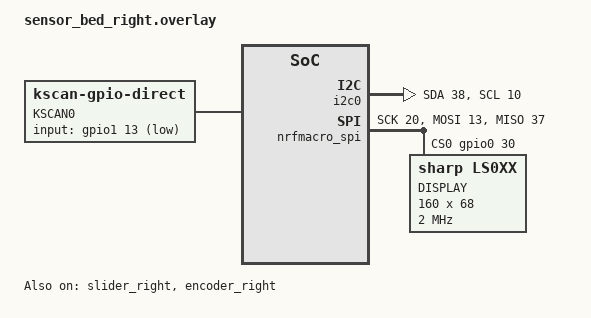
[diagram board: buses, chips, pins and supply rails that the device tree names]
/*
 * Copyright (c) 2020 The ZMK Contributors
 *
 * SPDX-License-Identifier: MIT
 */

#include "sensor_bed.dtsi"

/*  adjust matrix transform for pepripheral split */
&default_transform {
	col-offset = <1>;
};

/* Define kscan pins */
/ {
	kscan0: kscan0 {
		compatible = "zmk,kscan-gpio-direct";
		label = "KSCAN0";

		input-gpios
	  = <&gpio1 13 (GPIO_ACTIVE_LOW | GPIO_PULL_UP)>
    ;
	};
};

&kscan {
		touch_keys {
      kscan = <&slider_right>;
      column-offset = <1>;
		};
};

/* Enable the right slider and define its pins */
&slider_right {
  status = "okay";
  invert-direction;
	int-gpios = <&gpio0  31 (GPIO_ACTIVE_LOW | GPIO_PULL_UP)>;
};

/* Define sda and scl pins */
&i2c0 {
  status = "okay";
	sda-pin = <38>;
  scl-pin = <10>;
};

/* Define display */ 
&chosen {
	zephyr,display = &lcd;
};

&nrfmacro_spi {
  // activate this device
  status = "okay";

  compatible = "nordic,nrf-spim";
  sck-pin = <20>;
  mosi-pin = <13>;
  cs-gpios = <&gpio0 30 GPIO_ACTIVE_HIGH>;
  // Unused pin, needed for SPI definition, but not used by the display driver itself.
  miso-pin = <37>; // 1.05 is not broken out on the E73

	lcd: ls0xx@0 {
		compatible = "sharp,ls0xx";
		label = "DISPLAY";
		spi-max-frequency = <2000000>;
		reg = <0>;
		width = <160>;
		height = <68>;
		// extcomin-gpios = <&pro_micro 2 GPIO_ACTIVE_HIGH>;
		// extcomin-frequency = <60>;
		// disp-en-gpios = <&pro_micro 3 GPIO_ACTIVE_HIGH>; 
	};
};

/* Enable spi2 bus and the trackball, and define their pins */
// &spi2 {
//   status = "okay";
//   sck-pin = <24>;
//   mosi-pin = <9>;
//   miso-pin = <9>; // same as mosi (3-wire spi)
//   cs-gpios = <&gpio0 29 GPIO_ACTIVE_LOW>;
// };

// &trackball {
//   status = "okay";
//   irq-gpios = <&gpio0 2 (GPIO_ACTIVE_LOW | GPIO_PULL_UP)>;
// };

/* Enable the right encoder and define its pins */
&encoder_right {
	status = "okay";
	a-gpios = <&gpio1 4 (GPIO_ACTIVE_LOW | GPIO_PULL_UP)>;
	b-gpios = <&gpio0 5 (GPIO_ACTIVE_LOW | GPIO_PULL_UP)>;
};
